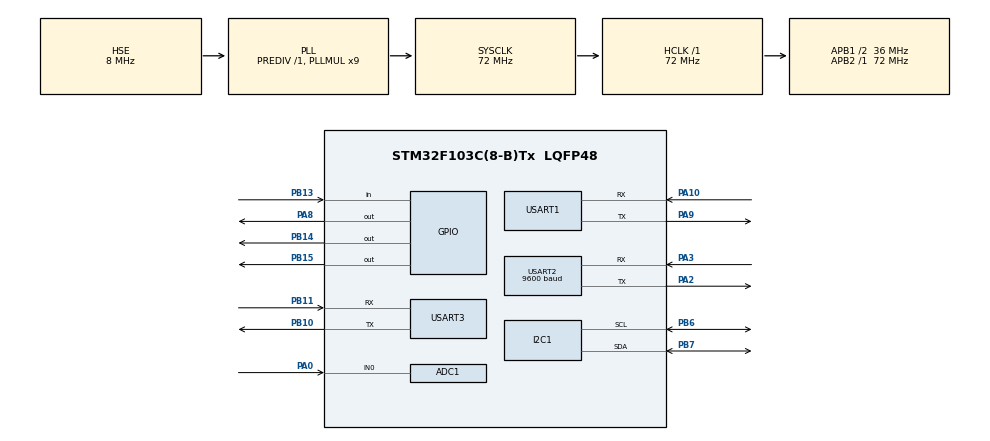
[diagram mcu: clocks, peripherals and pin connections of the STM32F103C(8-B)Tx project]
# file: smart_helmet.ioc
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ADC1.Channel-0\#ChannelRegularConversion=ADC_CHANNEL_0
ADC1.ContinuousConvMode=ENABLE
ADC1.NbrOfConversionFlag=1
ADC1.Rank-0\#ChannelRegularConversion=1
ADC1.SamplingTime-0\#ChannelRegularConversion=ADC_SAMPLETIME_1CYCLE_5
ADC1.master=1
Dma.ADC1.0.Direction=DMA_PERIPH_TO_MEMORY
Dma.ADC1.0.Instance=DMA1_Channel1
Dma.ADC1.0.MemDataAlignment=DMA_MDATAALIGN_WORD
Dma.ADC1.0.MemInc=DMA_MINC_ENABLE
Dma.ADC1.0.Mode=DMA_CIRCULAR
Dma.ADC1.0.PeriphDataAlignment=DMA_PDATAALIGN_WORD
Dma.ADC1.0.PeriphInc=DMA_PINC_DISABLE
Dma.ADC1.0.Priority=DMA_PRIORITY_MEDIUM
Dma.Request0=ADC1
Dma.Request1=USART2_RX
Dma.USART2_RX.1.Direction=DMA_PERIPH_TO_MEMORY
Dma.USART2_RX.1.Instance=DMA1_Channel6
Dma.USART2_RX.1.MemDataAlignment=DMA_MDATAALIGN_BYTE
Dma.USART2_RX.1.MemInc=DMA_MINC_ENABLE
Dma.USART2_RX.1.Mode=DMA_NORMAL
Dma.USART2_RX.1.PeriphDataAlignment=DMA_PDATAALIGN_BYTE
Dma.USART2_RX.1.PeriphInc=DMA_PINC_DISABLE
Dma.USART2_RX.1.Priority=DMA_PRIORITY_HIGH
I2C1.I2C_Mode=I2C_Fast
Mcu.Family=STM32F1
Mcu.Name=STM32F103C(8-B)Tx
Mcu.Package=LQFP48
NVIC.ADC1_2_IRQn=true\:2\:0\:true\:false\:true\:true\:true\:true
NVIC.DMA1_Channel1_IRQn=true\:0\:0\:false\:false\:true\:false\:true\:true
NVIC.DMA1_Channel6_IRQn=true\:0\:0\:false\:false\:true\:false\:true\:true
NVIC.PriorityGroup=NVIC_PRIORITYGROUP_4
NVIC.USART1_IRQn=true\:2\:0\:true\:false\:true\:true\:true\:true
PA0-WKUP.Signal=ADCx_IN0
PA10.Mode=Asynchronous
PA10.Signal=USART1_RX
PA13.Mode=Serial_Wire
PA13.Signal=SYS_JTMS-SWDIO
PA14.Mode=Serial_Wire
PA14.Signal=SYS_JTCK-SWCLK
PA2.Mode=Asynchronous
PA2.Signal=USART2_TX
PA3.Mode=Asynchronous
PA3.Signal=USART2_RX
PA8.GPIO_Speed=GPIO_SPEED_FREQ_HIGH
PA8.PinState=GPIO_PIN_SET
PA8.Signal=GPIO_Output
PA9.Mode=Asynchronous
PA9.Signal=USART1_TX
PB10.Mode=Asynchronous
PB10.Signal=USART3_TX
PB11.Mode=Asynchronous
PB11.Signal=USART3_RX
PB13.Signal=GPIO_Input
PB14.GPIO_ModeDefaultOutputPP=GPIO_MODE_OUTPUT_PP
PB14.GPIO_Speed=GPIO_SPEED_FREQ_HIGH
PB14.Signal=GPIO_Output
PB15.GPIO_ModeDefaultOutputPP=GPIO_MODE_OUTPUT_PP
PB15.GPIO_Speed=GPIO_SPEED_FREQ_HIGH
PB15.Signal=GPIO_Output
PB6.Mode=I2C
PB6.Signal=I2C1_SCL
PB7.Mode=I2C
PB7.Signal=I2C1_SDA
PD0-OSC_IN.Mode=HSE-External-Oscillator
PD0-OSC_IN.Signal=RCC_OSC_IN
PD1-OSC_OUT.Mode=HSE-External-Oscillator
PD1-OSC_OUT.Signal=RCC_OSC_OUT
ProjectManager.HeapSize=0x200
ProjectManager.StackSize=0x400
ProjectManager.TargetToolchain=MDK-ARM V5.32
RCC.ADCPresc=RCC_ADCPCLK2_DIV6
RCC.AHBFreq_Value=72000000
RCC.APB1CLKDivider=RCC_HCLK_DIV2
RCC.APB1Freq_Value=36000000
RCC.APB1TimFreq_Value=72000000
RCC.APB2Freq_Value=72000000
RCC.APB2TimFreq_Value=72000000
RCC.HCLKFreq_Value=72000000
RCC.PLLMUL=RCC_PLL_MUL9
RCC.PLLSourceVirtual=RCC_PLLSOURCE_HSE
RCC.SYSCLKFreq_VALUE=72000000
RCC.SYSCLKSource=RCC_SYSCLKSOURCE_PLLCLK
RCC.USBFreq_Value=72000000
SH.ADCx_IN0.0=ADC1_IN0,IN0
TIM1.Prescaler=72-1
USART1.VirtualMode=VM_ASYNC
USART2.BaudRate=9600
USART2.VirtualMode=VM_ASYNC
USART3.VirtualMode=VM_ASYNC
VP_TIM1_VS_ClockSourceINT.Mode=Internal
board=custom

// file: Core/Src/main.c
/* USER CODE BEGIN Header */

/**

 ******************************************************************************

 * @file           : main.c

 * @brief          : Main program body

 ******************************************************************************

 * @attention

 *

 * Copyright (c) 2025 STMicroelectronics.

 * All rights reserved.

 *

 * This software is licensed under terms that can be found in the LICENSE file

 * in the root directory of this software component.

 * If no LICENSE file comes with this software, it is provided AS-IS.

 *

 ******************************************************************************

 */

/* USER CODE END Header */

#include "main.h"

#include "adc.h"

#include "dma.h"

#include "i2c.h"

#include "tim.h"

#include "usart.h"

#include "gpio.h"

/* USER CODE BEGIN Includes */

#include "bsp_system.h"

/* USER CODE END Includes */

void SystemClock_Config(void);

int main(void)

{

  /* MCU Configuration--------------------------------------------------------*/

  /* Reset of all peripherals, Initializes the Flash interface and the Systick. */

  HAL_Init();

  /* Configure the system clock */

  SystemClock_Config();

  /* Initialize all configured peripherals */

  MX_GPIO_Init();

  MX_DMA_Init();

  MX_USART1_UART_Init();

  MX_ADC1_Init();

  MX_TIM1_Init();

  MX_I2C1_Init();

  MX_USART2_UART_Init();

  MX_USART3_UART_Init();

  /* USER CODE BEGIN 2 */

	HAL_ADC_Start_DMA(&hadc1, (uint32_t *)&dma_buff[0], 30); // 启动 ADC1 的 DMA 模式，将采集到的 30 个数据存储到 dma_buff 数组中

	esp_init(); // ESP-01S 初始化

	DHT11_Init(); // DHT11 温湿度传感器初始化

	MPU_Init(); // MPU6050 姿态传感器初始化

	mpu_dmp_init(); // DMP（数字运动处理器）初始化

	MAX30102_Init(); // MAX30102 心率血氧传感器初始化

//	atgm336h_init(); //ATGM336H定位传感器初始化

	scheduler_init(); // 任务调度器初始化

  /* USER CODE END 2 */

  /* Infinite loop */

  while (1)
  {

    /* USER CODE BEGIN 3 */

    scheduler_run(); //启动调度器

  }

  /* USER CODE END 3 */

}

void SystemClock_Config(void)

{

  RCC_OscInitTypeDef RCC_OscInitStruct = {0};

  RCC_ClkInitTypeDef RCC_ClkInitStruct = {0};

  RCC_PeriphCLKInitTypeDef PeriphClkInit = {0};

  /** Initializes the RCC Oscillators according to the specified parameters

  * in the RCC_OscInitTypeDef structure.

  */

  RCC_OscInitStruct.OscillatorType = RCC_OSCILLATORTYPE_HSE;

  RCC_OscInitStruct.HSEState = RCC_HSE_ON;

  RCC_OscInitStruct.HSEPredivValue = RCC_HSE_PREDIV_DIV1;

  RCC_OscInitStruct.HSIState = RCC_HSI_ON;

  RCC_OscInitStruct.PLL.PLLState = RCC_PLL_ON;

  RCC_OscInitStruct.PLL.PLLSource = RCC_PLLSOURCE_HSE;

  RCC_OscInitStruct.PLL.PLLMUL = RCC_PLL_MUL9;

  if (HAL_RCC_OscConfig(&RCC_OscInitStruct) != HAL_OK)

  {

    Error_Handler();

  }

  /** Initializes the CPU, AHB and APB buses clocks

  */

  RCC_ClkInitStruct.ClockType = RCC_CLOCKTYPE_HCLK|RCC_CLOCKTYPE_SYSCLK

                              |RCC_CLOCKTYPE_PCLK1|RCC_CLOCKTYPE_PCLK2;

  RCC_ClkInitStruct.SYSCLKSource = RCC_SYSCLKSOURCE_PLLCLK;

  RCC_ClkInitStruct.AHBCLKDivider = RCC_SYSCLK_DIV1;

  RCC_ClkInitStruct.APB1CLKDivider = RCC_HCLK_DIV2;

  RCC_ClkInitStruct.APB2CLKDivider = RCC_HCLK_DIV1;

  if (HAL_RCC_ClockConfig(&RCC_ClkInitStruct, FLASH_LATENCY_2) != HAL_OK)

  {

    Error_Handler();

  }

  PeriphClkInit.PeriphClockSelection = RCC_PERIPHCLK_ADC;

  PeriphClkInit.AdcClockSelection = RCC_ADCPCLK2_DIV6;

  if (HAL_RCCEx_PeriphCLKConfig(&PeriphClkInit) != HAL_OK)

  {

    Error_Handler();

  }

}

void Error_Handler(void)

{

  __disable_irq();
  while (1)
  {
  }

}
